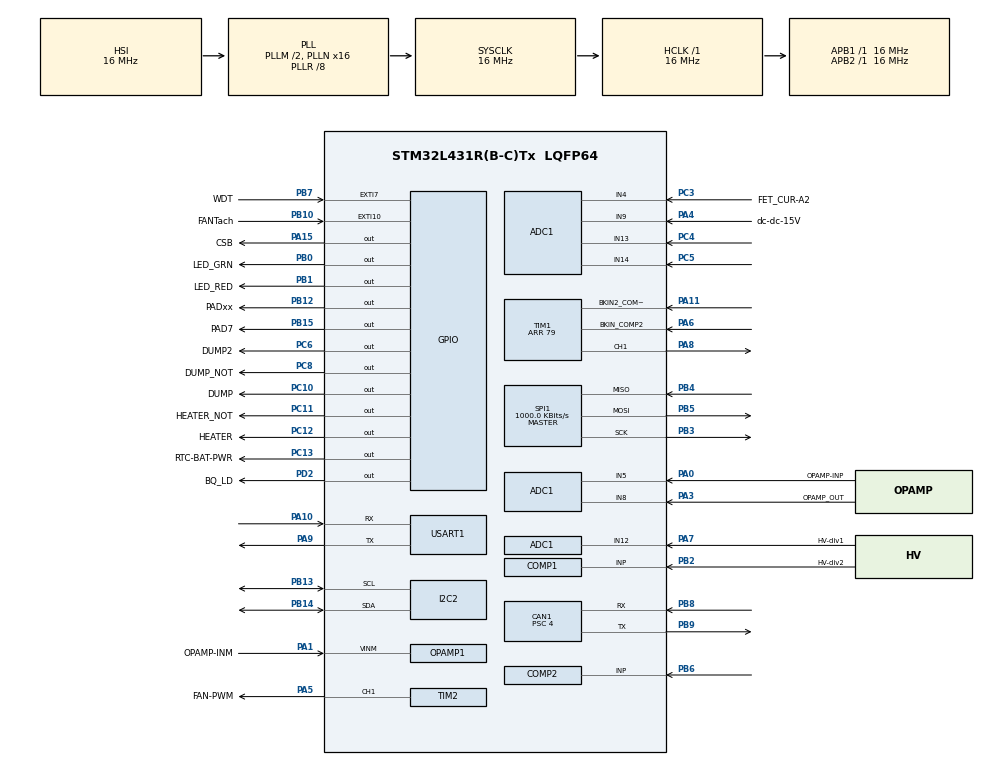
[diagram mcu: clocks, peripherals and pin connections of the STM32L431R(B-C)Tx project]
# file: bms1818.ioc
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ADC1.Channel-0\#ChannelRegularConversion=ADC_CHANNEL_4
ADC1.Channel-1\#ChannelRegularConversion=ADC_CHANNEL_5
ADC1.Channel-2\#ChannelRegularConversion=ADC_CHANNEL_8
ADC1.Channel-3\#ChannelRegularConversion=ADC_CHANNEL_12
ADC1.Channel-4\#ChannelRegularConversion=ADC_CHANNEL_13
ADC1.Channel-5\#ChannelRegularConversion=ADC_CHANNEL_14
ADC1.Channel-6\#ChannelRegularConversion=ADC_CHANNEL_VREFINT
ADC1.Channel-7\#ChannelRegularConversion=ADC_CHANNEL_TEMPSENSOR
ADC1.Channel-8\#ChannelRegularConversion=ADC_CHANNEL_9
ADC1.ContinuousConvMode=ENABLE
ADC1.DMAContinuousRequests=ENABLE
ADC1.EOCSelection=ADC_EOC_SEQ_CONV
ADC1.EnableInjectedConversion=DISABLE
ADC1.NbrOfConversion=9
ADC1.NbrOfConversionFlag=1
ADC1.OffsetNumber-0\#ChannelRegularConversion=ADC_OFFSET_NONE
ADC1.OffsetNumber-1\#ChannelRegularConversion=ADC_OFFSET_NONE
ADC1.OffsetNumber-2\#ChannelRegularConversion=ADC_OFFSET_NONE
ADC1.OffsetNumber-3\#ChannelRegularConversion=ADC_OFFSET_NONE
ADC1.OffsetNumber-4\#ChannelRegularConversion=ADC_OFFSET_NONE
ADC1.OffsetNumber-5\#ChannelRegularConversion=ADC_OFFSET_NONE
ADC1.OffsetNumber-6\#ChannelRegularConversion=ADC_OFFSET_NONE
ADC1.OffsetNumber-7\#ChannelRegularConversion=ADC_OFFSET_NONE
ADC1.OffsetNumber-8\#ChannelRegularConversion=ADC_OFFSET_NONE
ADC1.OversamplingMode=ENABLE
ADC1.Rank-0\#ChannelRegularConversion=1
ADC1.Rank-1\#ChannelRegularConversion=2
ADC1.Rank-2\#ChannelRegularConversion=3
ADC1.Rank-3\#ChannelRegularConversion=4
ADC1.Rank-4\#ChannelRegularConversion=5
ADC1.Rank-5\#ChannelRegularConversion=6
ADC1.Rank-6\#ChannelRegularConversion=7
ADC1.Rank-7\#ChannelRegularConversion=8
ADC1.Rank-8\#ChannelRegularConversion=9
ADC1.Ratio=ADC_OVERSAMPLING_RATIO_16
ADC1.SamplingTime-0\#ChannelRegularConversion=ADC_SAMPLETIME_2CYCLES_5
ADC1.SamplingTime-1\#ChannelRegularConversion=ADC_SAMPLETIME_24CYCLES_5
ADC1.SamplingTime-2\#ChannelRegularConversion=ADC_SAMPLETIME_24CYCLES_5
ADC1.SamplingTime-3\#ChannelRegularConversion=ADC_SAMPLETIME_640CYCLES_5
ADC1.SamplingTime-4\#ChannelRegularConversion=ADC_SAMPLETIME_247CYCLES_5
ADC1.SamplingTime-5\#ChannelRegularConversion=ADC_SAMPLETIME_247CYCLES_5
ADC1.SamplingTime-6\#ChannelRegularConversion=ADC_SAMPLETIME_247CYCLES_5
ADC1.SamplingTime-7\#ChannelRegularConversion=ADC_SAMPLETIME_247CYCLES_5
ADC1.SamplingTime-8\#ChannelRegularConversion=ADC_SAMPLETIME_247CYCLES_5
ADC1.master=1
CAN1.BS1=CAN_BS1_5TQ
CAN1.BS2=CAN_BS2_2TQ
CAN1.CalculateBaudRate=500000
CAN1.CalculateTimeBit=2000.00
CAN1.CalculateTimeQuantum=250.0
CAN1.NART=ENABLE
CAN1.Prescaler=4
CAN1.SJW=CAN_SJW_1TQ
COMP1.BlankingSrce=COMP_BLANKINGSRC_NONE
COMP2.BlankingSrce=COMP_BLANKINGSRC_NONE
DAC1.DAC_Channel-DAC_OUT2_Int=DAC_CHANNEL_2
Dma.ADC1.2.Direction=DMA_PERIPH_TO_MEMORY
Dma.ADC1.2.Instance=DMA1_Channel1
Dma.ADC1.2.MemDataAlignment=DMA_MDATAALIGN_HALFWORD
Dma.ADC1.2.MemInc=DMA_MINC_ENABLE
Dma.ADC1.2.Mode=DMA_CIRCULAR
Dma.ADC1.2.PeriphDataAlignment=DMA_PDATAALIGN_HALFWORD
Dma.ADC1.2.PeriphInc=DMA_PINC_DISABLE
Dma.ADC1.2.Priority=DMA_PRIORITY_LOW
Dma.I2C2_RX.3.Direction=DMA_PERIPH_TO_MEMORY
Dma.I2C2_RX.3.Instance=DMA1_Channel5
Dma.I2C2_RX.3.MemDataAlignment=DMA_MDATAALIGN_BYTE
Dma.I2C2_RX.3.MemInc=DMA_MINC_ENABLE
Dma.I2C2_RX.3.Mode=DMA_NORMAL
Dma.I2C2_RX.3.PeriphDataAlignment=DMA_PDATAALIGN_BYTE
Dma.I2C2_RX.3.PeriphInc=DMA_PINC_DISABLE
Dma.I2C2_RX.3.Priority=DMA_PRIORITY_LOW
Dma.I2C2_TX.4.Direction=DMA_MEMORY_TO_PERIPH
Dma.I2C2_TX.4.Instance=DMA1_Channel4
Dma.I2C2_TX.4.MemDataAlignment=DMA_MDATAALIGN_BYTE
Dma.I2C2_TX.4.MemInc=DMA_MINC_ENABLE
Dma.I2C2_TX.4.Mode=DMA_NORMAL
Dma.I2C2_TX.4.PeriphDataAlignment=DMA_PDATAALIGN_BYTE
Dma.I2C2_TX.4.PeriphInc=DMA_PINC_DISABLE
Dma.I2C2_TX.4.Priority=DMA_PRIORITY_LOW
Dma.Request0=USART1_RX
Dma.Request1=USART1_TX
Dma.Request2=ADC1
Dma.Request3=I2C2_RX
Dma.Request4=I2C2_TX
Dma.Request5=SPI1_RX
Dma.Request6=SPI1_TX
Dma.SPI1_RX.5.Direction=DMA_PERIPH_TO_MEMORY
Dma.SPI1_RX.5.Instance=DMA1_Channel2
Dma.SPI1_RX.5.MemDataAlignment=DMA_MDATAALIGN_BYTE
Dma.SPI1_RX.5.MemInc=DMA_MINC_ENABLE
Dma.SPI1_RX.5.Mode=DMA_NORMAL
Dma.SPI1_RX.5.PeriphDataAlignment=DMA_PDATAALIGN_BYTE
Dma.SPI1_RX.5.PeriphInc=DMA_PINC_DISABLE
Dma.SPI1_RX.5.Priority=DMA_PRIORITY_LOW
Dma.SPI1_TX.6.Direction=DMA_MEMORY_TO_PERIPH
Dma.SPI1_TX.6.Instance=DMA1_Channel3
Dma.SPI1_TX.6.MemDataAlignment=DMA_MDATAALIGN_BYTE
Dma.SPI1_TX.6.MemInc=DMA_MINC_ENABLE
Dma.SPI1_TX.6.Mode=DMA_NORMAL
Dma.SPI1_TX.6.PeriphDataAlignment=DMA_PDATAALIGN_BYTE
Dma.SPI1_TX.6.PeriphInc=DMA_PINC_DISABLE
Dma.SPI1_TX.6.Priority=DMA_PRIORITY_LOW
Dma.USART1_RX.0.Direction=DMA_PERIPH_TO_MEMORY
Dma.USART1_RX.0.Instance=DMA2_Channel7
Dma.USART1_RX.0.MemDataAlignment=DMA_MDATAALIGN_BYTE
Dma.USART1_RX.0.MemInc=DMA_MINC_ENABLE
Dma.USART1_RX.0.Mode=DMA_CIRCULAR
Dma.USART1_RX.0.PeriphDataAlignment=DMA_PDATAALIGN_BYTE
Dma.USART1_RX.0.PeriphInc=DMA_PINC_DISABLE
Dma.USART1_RX.0.Priority=DMA_PRIORITY_LOW
Dma.USART1_TX.1.Direction=DMA_MEMORY_TO_PERIPH
Dma.USART1_TX.1.Instance=DMA2_Channel6
Dma.USART1_TX.1.MemDataAlignment=DMA_MDATAALIGN_BYTE
Dma.USART1_TX.1.MemInc=DMA_MINC_ENABLE
Dma.USART1_TX.1.Mode=DMA_NORMAL
Dma.USART1_TX.1.PeriphDataAlignment=DMA_PDATAALIGN_BYTE
Dma.USART1_TX.1.PeriphInc=DMA_PINC_DISABLE
Dma.USART1_TX.1.Priority=DMA_PRIORITY_LOW
FREERTOS.Tasks01=defaultTask,24,448,StartDefaultTask,Default,NULL,Dynamic,NULL,NULL
FREERTOS.configTOTAL_HEAP_SIZE=12000
I2C2.Timing=0x00303D5B
Mcu.Family=STM32L4
Mcu.Name=STM32L431R(B-C)Tx
Mcu.Package=LQFP64
NVIC.CAN1_RX0_IRQn=true\:7\:0\:true\:false\:true\:true\:true\:true
NVIC.CAN1_RX1_IRQn=true\:7\:0\:true\:false\:true\:true\:true\:true
NVIC.CAN1_TX_IRQn=true\:7\:0\:true\:false\:true\:true\:true\:true
NVIC.DMA1_Channel1_IRQn=true\:6\:0\:true\:false\:true\:true\:false\:true
NVIC.DMA1_Channel2_IRQn=true\:5\:0\:false\:false\:true\:true\:false\:true
NVIC.DMA1_Channel3_IRQn=true\:5\:0\:false\:false\:true\:true\:false\:true
NVIC.DMA1_Channel4_IRQn=true\:5\:0\:false\:false\:true\:true\:false\:true
NVIC.DMA1_Channel5_IRQn=true\:5\:0\:false\:false\:true\:true\:false\:true
NVIC.DMA2_Channel6_IRQn=true\:6\:0\:true\:false\:true\:false\:false\:true
NVIC.DMA2_Channel7_IRQn=true\:6\:0\:true\:false\:true\:false\:false\:true
NVIC.EXTI9_5_IRQn=true\:5\:0\:false\:false\:true\:true\:true\:true
NVIC.PriorityGroup=NVIC_PRIORITYGROUP_4
NVIC.TIM1_BRK_TIM15_IRQn=true\:5\:0\:false\:false\:true\:true\:true\:true
NVIC.TIM1_UP_TIM16_IRQn=true\:0\:0\:false\:false\:true\:false\:false\:true
NVIC.TimeBase=TIM1_UP_TIM16_IRQn
NVIC.TimeBaseIP=TIM16
NVIC.USART1_IRQn=true\:10\:0\:true\:false\:true\:true\:true\:true
OPAMP1.PgaGain=OPAMP_PGA_GAIN_8
OPAMP1.PowerSupplyRange=OPAMP_POWERSUPPLY_HIGH
PA0.GPIO_Label=OPAMP-INP
PA0.Signal=SharedAnalog_PA0
PA1.GPIO_Label=OPAMP-INM
PA1.Signal=SharedAnalog_PA1
PA10.Mode=Asynchronous
PA10.Signal=USART1_RX
PA11.Mode=ExternalOutput_TIM1BKIN2
PA11.Signal=TIM1_BKIN2_COMP1
PA13\ (JTMS-SWDIO).Mode=Serial_Wire
PA13\ (JTMS-SWDIO).Signal=SYS_JTMS-SWDIO
PA14\ (JTCK-SWCLK).Mode=Serial_Wire
PA14\ (JTCK-SWCLK).Signal=SYS_JTCK-SWCLK
PA15\ (JTDI).GPIO_Label=CSB
PA15\ (JTDI).GPIO_Speed=GPIO_SPEED_FREQ_HIGH
PA15\ (JTDI).Signal=GPIO_Output
PA3.GPIO_Label=OPAMP_OUT
PA3.Signal=SharedAnalog_PA3
PA4.GPIO_Label=dc-dc-15V
PA4.Signal=SharedAnalog_PA4
PA5.GPIO_Label=FAN-PWM
PA5.Signal=S_TIM2_CH1
PA6.Mode=ExternalOutput_TIM1BKIN
PA6.Signal=TIM1_BKIN_COMP2
PA7.GPIO_Label=HV-div1
PA7.Signal=SharedAnalog_PA7
PA8.Signal=S_TIM1_CH1
PA9.Mode=Asynchronous
PA9.Signal=USART1_TX
PB0.GPIO_Label=LED_GRN
PB0.PinState=GPIO_PIN_SET
PB0.Signal=GPIO_Output
PB1.GPIO_Label=LED_RED
PB1.PinState=GPIO_PIN_SET
PB1.Signal=GPIO_Output
PB10.GPIO_Label=FANTach
PB10.Signal=GPXTI10
PB12.GPIO_Label=PADxx
PB12.Signal=GPIO_Output
PB13.GPIO_Pu=GPIO_NOPULL
PB13.GPIO_Speed=GPIO_SPEED_FREQ_LOW
PB13.Mode=I2C
PB13.Signal=I2C2_SCL
PB14.GPIO_Pu=GPIO_NOPULL
PB14.Mode=I2C
PB14.Signal=I2C2_SDA
PB15.GPIO_Label=PAD7
PB15.Signal=GPIO_Output
PB2.GPIO_Label=HV-div2
PB2.Signal=SharedAnalog_PB2
PB3\ (JTDO-TRACESWO).Mode=Full_Duplex_Master
PB3\ (JTDO-TRACESWO).Signal=SPI1_SCK
PB4\ (NJTRST).Mode=Full_Duplex_Master
PB4\ (NJTRST).Signal=SPI1_MISO
PB5.Mode=Full_Duplex_Master
PB5.Signal=SPI1_MOSI
PB6.Mode=INP
PB6.Signal=COMP2_INP
PB7.GPIO_Label=WDT
PB7.GPIO_PuPd=GPIO_PULLUP
PB7.Signal=GPXTI7
PB8.Mode=CAN_Activate
PB8.Signal=CAN1_RX
PB9.Mode=CAN_Activate
PB9.Signal=CAN1_TX
PC10.GPIO_Label=DUMP
PC10.Signal=GPIO_Output
PC11.GPIO_Label=HEATER_NOT
PC11.Signal=GPIO_Output
PC12.GPIO_Label=HEATER
PC12.Signal=GPIO_Output
PC13.GPIO_Label=RTC-BAT-PWR
PC13.Signal=GPIO_Output
PC3.GPIO_Label=FET_CUR-A2
PC3.Signal=SharedAnalog_PC3
PC4.Signal=ADCx_IN13
PC5.Signal=ADCx_IN14
PC6.GPIO_Label=DUMP2
PC6.GPIO_PuPd=GPIO_PULLDOWN
PC6.Signal=GPIO_Output
PC8.GPIO_Label=DUMP_NOT
PC8.Signal=GPIO_Output
PD2.GPIO_Label=BQ_LD
PD2.Signal=GPIO_Output
PH0-OSC_IN\ (PH0).Mode=HSE-External-Oscillator
PH0-OSC_IN\ (PH0).Signal=RCC_OSC_IN
PH1-OSC_OUT\ (PH1).Mode=HSE-External-Oscillator
PH1-OSC_OUT\ (PH1).Signal=RCC_OSC_OUT
ProjectManager.HeapSize=0x200
ProjectManager.StackSize=0x400
ProjectManager.TargetToolchain=Makefile
RCC.ADCFreq_Value=16000000
RCC.AHBFreq_Value=16000000
RCC.APB1Freq_Value=16000000
RCC.APB1TimFreq_Value=16000000
RCC.APB2Freq_Value=16000000
RCC.APB2TimFreq_Value=16000000
RCC.CortexFreq_Value=16000000
RCC.HCLKFreq_Value=16000000
RCC.HSE_VALUE=16000000
RCC.HSI48_VALUE=48000000
RCC.HSI_VALUE=16000000
RCC.I2C1CLockSelection=RCC_I2C1CLKSOURCE_SYSCLK
RCC.MSIClockRange=RCC_MSIRANGE_7
RCC.MSI_VALUE=8000000
RCC.PLLM=2
RCC.PLLN=16
RCC.PLLR=RCC_PLLR_DIV8
RCC.PLLSAI1R=RCC_PLLR_DIV4
RCC.PLLSourceVirtual=RCC_PLLSOURCE_HSI
RCC.SYSCLKFreq_VALUE=16000000
RCC.SYSCLKSource=RCC_SYSCLKSOURCE_PLLCLK
RCC.USART1CLockSelection=RCC_USART1CLKSOURCE_HSI
RCC.VCOOutputFreq_Value=128000000
SH.ADCx_IN13.0=ADC1_IN13,IN13-Single-Ended
SH.ADCx_IN14.0=ADC1_IN14,IN14-Single-Ended
SH.S_TIM1_CH1.0=TIM1_CH1,PWM Generation1 CH1
SH.S_TIM2_CH1.0=TIM2_CH1,PWM Generation1 CH1
SH.SharedAnalog_PA0.0=GPIO_Analog
SH.SharedAnalog_PA0.1=ADC1_IN5,IN5-Single-Ended
SH.SharedAnalog_PA0.2=OPAMP1_VINP,PGA Connected
SH.SharedAnalog_PA1.0=GPIO_Analog
SH.SharedAnalog_PA1.1=OPAMP1_VINM,PGA Connected
SH.SharedAnalog_PA3.0=GPIO_Analog
SH.SharedAnalog_PA3.1=ADC1_IN8,IN8-Single-Ended
SH.SharedAnalog_PA3.2=OPAMP1_VOUT,PGA Connected
SH.SharedAnalog_PA4.0=GPIO_Analog
SH.SharedAnalog_PA4.1=ADC1_IN9,IN9-Single-Ended
SH.SharedAnalog_PA7.0=GPIO_Analog
SH.SharedAnalog_PA7.1=ADC1_IN12,IN12-Single-Ended
SH.SharedAnalog_PB2.0=GPIO_Analog
SH.SharedAnalog_PB2.1=COMP1_INP,INP
SH.SharedAnalog_PC3.0=GPIO_Analog
SH.SharedAnalog_PC3.1=ADC1_IN4,IN4-Single-Ended
SPI1.BaudRatePrescaler=SPI_BAUDRATEPRESCALER_16
SPI1.CLKPolarity=SPI_POLARITY_HIGH
SPI1.CalculateBaudRate=1000.0 KBits/s
SPI1.DataSize=SPI_DATASIZE_8BIT
SPI1.Direction=SPI_DIRECTION_2LINES
SPI1.Mode=SPI_MODE_MASTER
SPI1.NSSPMode=SPI_NSS_PULSE_DISABLE
SPI1.VirtualType=VM_MASTER
TIM1.AutomaticOutput=TIM_AUTOMATICOUTPUT_ENABLE
TIM1.Channel-PWM\ Generation1\ CH1=TIM_CHANNEL_1
TIM1.Period=79
TIM1.SourceBRK2COMP1=TIM_BREAKINPUTSOURCE_ENABLE
TIM1.SourceBRK2COMP2=TIM_BREAKINPUTSOURCE_DISABLE
TIM1.SourceBRKCOMP2=TIM_BREAKINPUTSOURCE_ENABLE
TIM15.Channel-Output\ Compare1\ No\ Output=TIM_CHANNEL_1
TIM15.Prescaler=16
TIM2.Channel-PWM\ Generation1\ CH1=TIM_CHANNEL_1
USART1.OverSampling=UART_OVERSAMPLING_8
USART1.VirtualMode-Asynchronous=VM_ASYNC
VP_ADC1_TempSens_Input.Mode=IN-TempSens
VP_ADC1_Vref_Input.Mode=IN-Vrefint
VP_COMP1_VS_DACOUT1.Mode=INM_DACOUT1
VP_COMP2_VS_DACOUT2.Mode=INM_DACOUT2
VP_DAC1_VS_DACI1.Mode=DAC_OUT1_Int
VP_DAC1_VS_DACI2.Mode=DAC_OUT2_Int
VP_FREERTOS_VS_CMSIS_V2.Mode=CMSIS_V2
VP_RTC_VS_RTC_Activate.Mode=RTC_Enabled
VP_RTC_VS_RTC_Calendar.Mode=RTC_Calendar
VP_SYS_VS_tim16.Mode=TIM16
VP_TIM15_VS_ClockSourceINT.Mode=Internal
VP_TIM15_VS_no_output1.Mode=Output Compare1 No Output
VP_TIM1_VS_BKIN2_COMP1.Mode=Activate-Break-Input-2-COMP1
VP_TIM1_VS_BKIN_COMP2.Mode=Activate-Break-Input-COMP2
VP_TIM1_VS_ClockSourceINT.Mode=Internal
VP_TIM2_VS_ClockSourceINT.Mode=Internal
board=custom

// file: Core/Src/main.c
/* USER CODE BEGIN Header */
/**
  ******************************************************************************
  * @file           : main.c
  * @brief          : Main program body
  ******************************************************************************
  * @attention
  *
  * <h2><center>&copy; Copyright (c) 2021 STMicroelectronics.
  * All rights reserved.</center></h2>
  *
  * This software component is licensed by ST under Ultimate Liberty license
  * SLA0044, the "License"; You may not use this file except in compliance with
  * the License. You may obtain a copy of the License at:
  *                             www.st.com/SLA0044
  *
  ******************************************************************************
  */
/*Command line to load program over CAN
:~~/GliderWinchCommons/embed/svn_discoveryf4/PC/sensor/CANldr/trunk$ ./CANldr 127.0.0.1 32123 B0A00000 ~/GliderWinchItems/BMS/bmsadbms1818/build/bms1818.xbin; echo $?
*/
/* USER CODE END Header */
#include "main.h"
#include "cmsis_os.h"

/* USER CODE BEGIN Includes */
#include <string.h>
#include "morse.h"
#include "DTW_counter.h"
#include "fetonoff.h"

#include "adcparams.h"
#include "SerialTaskSend.h"
#include "SerialTaskReceive.h"
#include "CanTask.h"
#include "can_iface.h"
#include "canfilter_setup.h"
#include "getserialbuf.h"
#include "yprintf.h"
#include "DTW_counter.h"
#include "BQTask.h"
#include "bqview.h"
#include "bqcellbal.h"
#include "bq_func_init.h"
#include "bq_items.h"
#include "ADCTask.h"
#include "MailboxTask.h"
#include "CanCommTask.h"
#include "BMSTask.h"
#include "fanop.h"
#include "chgr_items.h"
#include "bmsspi.h"
#include "bms_items.h"
#include "rtcregs.h"

#include "FreeRTOS.h"
#include "semphr.h"
/* USER CODE END Includes */

/* USER CODE BEGIN PTD */
uint32_t timectr = 0;
struct CAN_CTLBLOCK* pctl0; // Pointer to CAN1 control block
//struct CAN_CTLBLOCK* pctl1; // Pointer to CAN2 control block

uint32_t debugTX1b;
uint32_t debugTX1b_prev;

uint32_t debugTX1c;
uint32_t debugTX1c_prev;

uint32_t debug03;
uint32_t debug03_prev;

uint32_t dbgwarning;

//extern osThreadId SerialTaskHandle;
//extern osThreadId CanTxTaskHandle;
//extern osThreadId CanRxTaskHandle;
//extern osThreadId SerialTaskReceiveHandle;

uint16_t m_trap = 450; // Trap codes for MX Init() and Error Handler

uint8_t canflag;
uint8_t canflag1;
//uint8_t canflag2;

int8_t rtcregs_ret; // RTC register init return

const uint32_t i_am_canid = I_AM_CANID;

/* USER CODE END PTD */

/* USER CODE BEGIN PM */
  /*
  Timer usage
                         1    2   3   4   auto  auto
  TIM1 charger control  PWM   x   x   x  comp1 comp2
                        PA8               PA6   PA11
  TIM2 FAN PWM TACH     PWM   x  IC   x
                        PA5     PB10
  TIM7  System          x

  TIM15 SPI/ADC/BMS     OC    x

  */
/* USER CODE END PM */

ADC_HandleTypeDef hadc1;
DMA_HandleTypeDef hdma_adc1;

CAN_HandleTypeDef hcan1;

COMP_HandleTypeDef hcomp1;
COMP_HandleTypeDef hcomp2;

DAC_HandleTypeDef hdac1;

I2C_HandleTypeDef hi2c2;
DMA_HandleTypeDef hdma_i2c2_rx;
DMA_HandleTypeDef hdma_i2c2_tx;

OPAMP_HandleTypeDef hopamp1;

RTC_HandleTypeDef hrtc;

SPI_HandleTypeDef hspi1;
DMA_HandleTypeDef hdma_spi1_rx;
DMA_HandleTypeDef hdma_spi1_tx;

TIM_HandleTypeDef htim1;
TIM_HandleTypeDef htim2;
TIM_HandleTypeDef htim15;

UART_HandleTypeDef huart1;
DMA_HandleTypeDef hdma_usart1_rx;
DMA_HandleTypeDef hdma_usart1_tx;

/* Definitions for defaultTask */
osThreadId_t defaultTaskHandle;
const osThreadAttr_t defaultTask_attributes = {
  .name = "defaultTask",
  .stack_size = 448 * 4,
  .priority = (osPriority_t) osPriorityNormal,
};
/* USER CODE BEGIN PV */
uint16_t errorcode;
/* USER CODE END PV */

void SystemClock_Config(void);
static void MX_GPIO_Init(void);
static void MX_DMA_Init(void);
static void MX_ADC1_Init(void);
static void MX_CAN1_Init(void);
static void MX_RTC_Init(void);
static void MX_TIM2_Init(void);
static void MX_USART1_UART_Init(void);
static void MX_COMP1_Init(void);
static void MX_DAC1_Init(void);
static void MX_TIM1_Init(void);
static void MX_TIM15_Init(void);
static void MX_OPAMP1_Init(void);
static void MX_SPI1_Init(void);
static void MX_I2C2_Init(void);
static void MX_COMP2_Init(void);
void StartDefaultTask(void *argument);

int main(void)
{
  /* USER CODE BEGIN 1 */
  BaseType_t ret;    // Used for returns from function calls
  osThreadId Thrdret;  // Return from thread create
  /* USER CODE END 1 */

  /* MCU Configuration--------------------------------------------------------*/

  /* Reset of all peripherals, Initializes the Flash interface and the Systick. */
  HAL_Init();

  /* USER CODE BEGIN Init */
  DTW_counter_init();
  /* USER CODE END Init */

  /* Configure the system clock */
  SystemClock_Config();

  /* USER CODE BEGIN SysInit */
#define NUMCIRBCB1  16 // Size of circular buffer of BCB for usart3
  ret = xSerialTaskSendAdd(&HUARTMON, NUMCIRBCB1, 1); // dma
  if (ret < 0) morse_trap(111); // Panic LED flashing
  /* USER CODE END SysInit */

  /* Initialize all configured peripherals */
  MX_GPIO_Init();
  MX_DMA_Init();
  MX_ADC1_Init();
  MX_CAN1_Init();
  MX_RTC_Init();
  MX_TIM2_Init();
  MX_USART1_UART_Init();
  MX_COMP1_Init();
  MX_DAC1_Init();
  MX_TIM1_Init();
  MX_TIM15_Init();
  MX_OPAMP1_Init();
  MX_SPI1_Init();
  MX_I2C2_Init();
  MX_COMP2_Init();
  /* USER CODE BEGIN 2 */
  /* CAN ID for this node is passed in to make from command line. */
//  i_am_canid = I_AM_CANID;
  /* USER CODE END 2 */

  /* Init scheduler */
  osKernelInitialize();

  /* USER CODE BEGIN RTOS_SEMAPHORES */
  /* add semaphores, ... */
  /* Setup semaphore for yprint and sprintf et al. */
  yprintf_init();
  /* USER CODE END RTOS_SEMAPHORES */

  /* Create the thread(s) */
  /* creation of defaultTask */
  defaultTaskHandle = osThreadNew(StartDefaultTask, NULL, &defaultTask_attributes);

  /* USER CODE BEGIN RTOS_THREADS */
  /* add threads, ... */

  Thrdret = xADCTaskCreate(osPriorityNormal+2); // (arg) = priority
  if (Thrdret == NULL) morse_trap(117);

  /* Create serial task (priority) */
  // Task handle "osThreadId SerialTaskHandle" is global
  Thrdret = xSerialTaskSendCreate(osPriorityNormal); // Create task and set Task priority
  if (Thrdret == NULL) morse_trap(112);

    /* Add bcb circular buffer to SerialTaskSend for usart3 -- PC monitor */
  #define NUMCIRBCB3  16 // Size of circular buffer of BCB for usart3
  ret = xSerialTaskSendAdd(&HUARTMON, NUMCIRBCB3, 1); // dma
  if (ret < 0) morse_trap(14); // Panic LED flashing

  /* Setup TX linked list for CAN  */
   // CAN1 (CAN_HandleTypeDef *phcan, uint8_t canidx, uint16_t numtx, uint16_t numrx);
  pctl0 = can_iface_init(&hcan1, 0, 96, 32);
  if (pctl0 == NULL) morse_trap(118); // Panic LED flashing
  if (pctl0->ret < 0) morse_trap(119);

  /* Create serial receiving task. */
  //ret = xSerialTaskReceiveCreate(osPriorityNormal);
  //if (ret != pdPASS) morse_trap(113);

  /* BQTask. */
//  TaskHandle_t retT = xBQTaskCreate(osPriorityNormal);
//  if (retT == NULL) morse_trap(114);

  /* USER CODE END RTOS_THREADS */

  /* USER CODE BEGIN RTOS_EVENTS */
  /* add events, ... */
  // Initialize struct for BQ. */
  bq_func_init();

  /* definition and creation of CanTxTask - CAN driver TX interface. */
  QueueHandle_t QHret = xCanTxTaskCreate(osPriorityNormal+1, 48); // CanTask priority, Number of msgs in queue
  if (QHret == NULL) morse_trap(120); // Panic LED flashing

  /* definition and creation of CanRxTask - CAN driver RX interface. */
  /* The MailboxTask takes care of the CANRx                         */
//  Qidret = xCanRxTaskCreate(1, 32); // CanTask priority, Number of msgs in queue
//  if (Qidret < 0) morse_trap(6); // Panic LED flashing

  /* Create MailboxTask */
  xMailboxTaskCreate(osPriorityNormal+1); // (arg) = priority

  /* Create Mailbox control block w 'take' pointer for each CAN module. */
  struct MAILBOXCANNUM* pmbxret;
  // (CAN1 control block pointer, size of circular buffer)
  pmbxret = MailboxTask_add_CANlist(pctl0, 32);
  if (pmbxret == NULL) morse_trap(215);

  /* Setup CAN hardware filters to default to accept all ids. */
  HAL_StatusTypeDef Cret;
  Cret = canfilter_setup_first(0, &hcan1, 15); // CAN1
  if (Cret == HAL_ERROR) morse_trap(122);

  TaskHandle_t retT = xBMSTaskCreate(osPriorityNormal+2);
//  TaskHandle_t retT = xBMSTaskCreate(osPriorityNormal+1);
  if (retT == NULL) morse_trap(123);

  /* CAN communication */
  retT = xCanCommCreate(osPriorityNormal+2);
  if (retT == NULL) morse_trap(121);

    /* Select interrupts for CAN1 */
  HAL_CAN_ActivateNotification(&hcan1, \
    CAN_IT_TX_MAILBOX_EMPTY     |  \
    CAN_IT_RX_FIFO0_MSG_PENDING |  \
    CAN_IT_RX_FIFO1_MSG_PENDING    );

  /* Init some things used by tasks. */
  //bq_func_init();
  chgr_items_init();
  fanop_init();
  bmsspi_preinit();
  rtcregs_ret = rtcregs_init();

  /* This will run the 5 and 3.3v regulators from the ribbon
     Cell #3 when the CAN power has been removed. */
  HAL_GPIO_WritePin(GPIOC,GPIO_PIN_13,GPIO_PIN_SET); // ON
//HAL_GPIO_WritePin(GPIOC,GPIO_PIN_13,GPIO_PIN_RESET); // OFF
  /* USER CODE END RTOS_EVENTS */

  /* Start scheduler */
  osKernelStart();

  /* We should never get here as control is now taken by the scheduler */
  /* Infinite loop */
  while (1)
  {

  }
}

void SystemClock_Config(void)
{
  RCC_OscInitTypeDef RCC_OscInitStruct = {0};
  RCC_ClkInitTypeDef RCC_ClkInitStruct = {0};

  /** Configure the main internal regulator output voltage
  */
  if (HAL_PWREx_ControlVoltageScaling(PWR_REGULATOR_VOLTAGE_SCALE1) != HAL_OK)
  {
    Error_Handler();
  }
  /** Initializes the RCC Oscillators according to the specified parameters
  * in the RCC_OscInitTypeDef structure.
  */
  RCC_OscInitStruct.OscillatorType = RCC_OSCILLATORTYPE_HSI|RCC_OSCILLATORTYPE_LSI;
  RCC_OscInitStruct.HSIState = RCC_HSI_ON;
  RCC_OscInitStruct.HSICalibrationValue = RCC_HSICALIBRATION_DEFAULT;
  RCC_OscInitStruct.LSIState = RCC_LSI_ON;
  RCC_OscInitStruct.PLL.PLLState = RCC_PLL_ON;
  RCC_OscInitStruct.PLL.PLLSource = RCC_PLLSOURCE_HSI;
  RCC_OscInitStruct.PLL.PLLM = 2;
  RCC_OscInitStruct.PLL.PLLN = 16;
  RCC_OscInitStruct.PLL.PLLP = RCC_PLLP_DIV7;
  RCC_OscInitStruct.PLL.PLLQ = RCC_PLLQ_DIV2;
  RCC_OscInitStruct.PLL.PLLR = RCC_PLLR_DIV8;
  if (HAL_RCC_OscConfig(&RCC_OscInitStruct) != HAL_OK)
  {
    Error_Handler();
  }
  /** Initializes the CPU, AHB and APB buses clocks
  */
  RCC_ClkInitStruct.ClockType = RCC_CLOCKTYPE_HCLK|RCC_CLOCKTYPE_SYSCLK
                              |RCC_CLOCKTYPE_PCLK1|RCC_CLOCKTYPE_PCLK2;
  RCC_ClkInitStruct.SYSCLKSource = RCC_SYSCLKSOURCE_PLLCLK;
  RCC_ClkInitStruct.AHBCLKDivider = RCC_SYSCLK_DIV1;
  RCC_ClkInitStruct.APB1CLKDivider = RCC_HCLK_DIV1;
  RCC_ClkInitStruct.APB2CLKDivider = RCC_HCLK_DIV1;

  if (HAL_RCC_ClockConfig(&RCC_ClkInitStruct, FLASH_LATENCY_0) != HAL_OK)
  {
    Error_Handler();
  }
}

static void MX_ADC1_Init(void)
{

  ADC_ChannelConfTypeDef sConfig = {0};

  /** Common config
  */
  hadc1.Instance = ADC1;
  hadc1.Init.ClockPrescaler = ADC_CLOCK_ASYNC_DIV1;
  hadc1.Init.Resolution = ADC_RESOLUTION_12B;
  hadc1.Init.DataAlign = ADC_DATAALIGN_RIGHT;
  hadc1.Init.ScanConvMode = ADC_SCAN_ENABLE;
  hadc1.Init.EOCSelection = ADC_EOC_SEQ_CONV;
  hadc1.Init.LowPowerAutoWait = DISABLE;
  hadc1.Init.ContinuousConvMode = ENABLE;
  hadc1.Init.NbrOfConversion = 9;
  hadc1.Init.DiscontinuousConvMode = DISABLE;
  hadc1.Init.ExternalTrigConv = ADC_SOFTWARE_START;
  hadc1.Init.ExternalTrigConvEdge = ADC_EXTERNALTRIGCONVEDGE_NONE;
  hadc1.Init.DMAContinuousRequests = ENABLE;
  hadc1.Init.Overrun = ADC_OVR_DATA_PRESERVED;
  hadc1.Init.OversamplingMode = ENABLE;
  hadc1.Init.Oversampling.Ratio = ADC_OVERSAMPLING_RATIO_16;
  hadc1.Init.Oversampling.RightBitShift = ADC_RIGHTBITSHIFT_NONE;
  hadc1.Init.Oversampling.TriggeredMode = ADC_TRIGGEREDMODE_SINGLE_TRIGGER;
  hadc1.Init.Oversampling.OversamplingStopReset = ADC_REGOVERSAMPLING_CONTINUED_MODE;
  if (HAL_ADC_Init(&hadc1) != HAL_OK)
  {
    Error_Handler();
  }
  /** Configure Regular Channel
  */
  sConfig.Channel = ADC_CHANNEL_4;
  sConfig.Rank = ADC_REGULAR_RANK_1;
  sConfig.SamplingTime = ADC_SAMPLETIME_2CYCLES_5;
  sConfig.SingleDiff = ADC_SINGLE_ENDED;
  sConfig.OffsetNumber = ADC_OFFSET_NONE;
  sConfig.Offset = 0;
  if (HAL_ADC_ConfigChannel(&hadc1, &sConfig) != HAL_OK)
  {
    Error_Handler();
  }
  /** Configure Regular Channel
  */
  sConfig.Channel = ADC_CHANNEL_5;
  sConfig.Rank = ADC_REGULAR_RANK_2;
  sConfig.SamplingTime = ADC_SAMPLETIME_24CYCLES_5;
  if (HAL_ADC_ConfigChannel(&hadc1, &sConfig) != HAL_OK)
  {
    Error_Handler();
  }
  /** Configure Regular Channel
  */
  sConfig.Channel = ADC_CHANNEL_8;
  sConfig.Rank = ADC_REGULAR_RANK_3;
  if (HAL_ADC_ConfigChannel(&hadc1, &sConfig) != HAL_OK)
  {
    Error_Handler();
  }
  /** Configure Regular Channel
  */
  sConfig.Channel = ADC_CHANNEL_12;
  sConfig.Rank = ADC_REGULAR_RANK_4;
  sConfig.SamplingTime = ADC_SAMPLETIME_640CYCLES_5;
  if (HAL_ADC_ConfigChannel(&hadc1, &sConfig) != HAL_OK)
  {
    Error_Handler();
  }
  /** Configure Regular Channel
  */
  sConfig.Channel = ADC_CHANNEL_13;
  sConfig.Rank = ADC_REGULAR_RANK_5;
  sConfig.SamplingTime = ADC_SAMPLETIME_247CYCLES_5;
  if (HAL_ADC_ConfigChannel(&hadc1, &sConfig) != HAL_OK)
  {
    Error_Handler();
  }
  /** Configure Regular Channel
  */
  sConfig.Channel = ADC_CHANNEL_14;
  sConfig.Rank = ADC_REGULAR_RANK_6;
  if (HAL_ADC_ConfigChannel(&hadc1, &sConfig) != HAL_OK)
  {
    Error_Handler();
  }
  /** Configure Regular Channel
  */
  sConfig.Channel = ADC_CHANNEL_VREFINT;
  sConfig.Rank = ADC_REGULAR_RANK_7;
  if (HAL_ADC_ConfigChannel(&hadc1, &sConfig) != HAL_OK)
  {
    Error_Handler();
  }
  /** Configure Regular Channel
  */
  sConfig.Channel = ADC_CHANNEL_TEMPSENSOR;
  sConfig.Rank = ADC_REGULAR_RANK_8;
  if (HAL_ADC_ConfigChannel(&hadc1, &sConfig) != HAL_OK)
  {
    Error_Handler();
  }
  /** Configure Regular Channel
  */
  sConfig.Channel = ADC_CHANNEL_9;
  sConfig.Rank = ADC_REGULAR_RANK_9;
  if (HAL_ADC_ConfigChannel(&hadc1, &sConfig) != HAL_OK)
  {
    Error_Handler();
  }

}

static void MX_CAN1_Init(void)
{

  hcan1.Instance = CAN1;
  hcan1.Init.Prescaler = 4;
  hcan1.Init.Mode = CAN_MODE_NORMAL;
  hcan1.Init.SyncJumpWidth = CAN_SJW_1TQ;
  hcan1.Init.TimeSeg1 = CAN_BS1_5TQ;
  hcan1.Init.TimeSeg2 = CAN_BS2_2TQ;
  hcan1.Init.TimeTriggeredMode = DISABLE;
  hcan1.Init.AutoBusOff = DISABLE;
  hcan1.Init.AutoWakeUp = DISABLE;
  hcan1.Init.AutoRetransmission = ENABLE;
  hcan1.Init.ReceiveFifoLocked = DISABLE;
  hcan1.Init.TransmitFifoPriority = DISABLE;
  if (HAL_CAN_Init(&hcan1) != HAL_OK)
  {
    Error_Handler();
  }

}

static void MX_COMP1_Init(void)
{

  /* USER CODE BEGIN COMP1_Init 0 */
  errorcode = 998; // Error_Handler morse_trap code

  /* USER CODE END COMP1_Init 0 */

  hcomp1.Instance = COMP1;
  hcomp1.Init.InvertingInput = COMP_INPUT_MINUS_DAC1_CH1;
  hcomp1.Init.NonInvertingInput = COMP_INPUT_PLUS_IO2;
  hcomp1.Init.OutputPol = COMP_OUTPUTPOL_NONINVERTED;
  hcomp1.Init.Hysteresis = COMP_HYSTERESIS_NONE;
  hcomp1.Init.BlankingSrce = COMP_BLANKINGSRC_NONE;
  hcomp1.Init.Mode = COMP_POWERMODE_HIGHSPEED;
  hcomp1.Init.WindowMode = COMP_WINDOWMODE_DISABLE;
  hcomp1.Init.TriggerMode = COMP_TRIGGERMODE_NONE;
  if (HAL_COMP_Init(&hcomp1) != HAL_OK)
  {
    Error_Handler();
  }

}

static void MX_COMP2_Init(void)
{

  /* USER CODE BEGIN COMP2_Init 0 */
  errorcode = 997; // Error_Handler morse_trap code

  /* USER CODE END COMP2_Init 0 */

  hcomp2.Instance = COMP2;
  hcomp2.Init.InvertingInput = COMP_INPUT_MINUS_DAC1_CH2;
  hcomp2.Init.NonInvertingInput = COMP_INPUT_PLUS_IO2;
  hcomp2.Init.OutputPol = COMP_OUTPUTPOL_NONINVERTED;
  hcomp2.Init.Hysteresis = COMP_HYSTERESIS_NONE;
  hcomp2.Init.BlankingSrce = COMP_BLANKINGSRC_NONE;
  hcomp2.Init.Mode = COMP_POWERMODE_HIGHSPEED;
  hcomp2.Init.WindowMode = COMP_WINDOWMODE_DISABLE;
  hcomp2.Init.TriggerMode = COMP_TRIGGERMODE_NONE;
  if (HAL_COMP_Init(&hcomp2) != HAL_OK)
  {
    Error_Handler();
  }

}

static void MX_DAC1_Init(void)
{

  DAC_ChannelConfTypeDef sConfig = {0};

  /** DAC Initialization
  */
  hdac1.Instance = DAC1;
  if (HAL_DAC_Init(&hdac1) != HAL_OK)
  {
    Error_Handler();
  }
  /** DAC channel OUT1 config
  */
  sConfig.DAC_SampleAndHold = DAC_SAMPLEANDHOLD_DISABLE;
  sConfig.DAC_Trigger = DAC_TRIGGER_NONE;
  sConfig.DAC_OutputBuffer = DAC_OUTPUTBUFFER_DISABLE;
  sConfig.DAC_ConnectOnChipPeripheral = DAC_CHIPCONNECT_ENABLE;
  sConfig.DAC_UserTrimming = DAC_TRIMMING_FACTORY;
  if (HAL_DAC_ConfigChannel(&hdac1, &sConfig, DAC_CHANNEL_1) != HAL_OK)
  {
    Error_Handler();
  }
  /** DAC channel OUT2 config
  */
  if (HAL_DAC_ConfigChannel(&hdac1, &sConfig, DAC_CHANNEL_2) != HAL_OK)
  {
    Error_Handler();
  }

}

static void MX_I2C2_Init(void)
{

  hi2c2.Instance = I2C2;
  hi2c2.Init.Timing = 0x00303D5B;
  hi2c2.Init.OwnAddress1 = 0;
  hi2c2.Init.AddressingMode = I2C_ADDRESSINGMODE_7BIT;
  hi2c2.Init.DualAddressMode = I2C_DUALADDRESS_DISABLE;
  hi2c2.Init.OwnAddress2 = 0;
  hi2c2.Init.OwnAddress2Masks = I2C_OA2_NOMASK;
  hi2c2.Init.GeneralCallMode = I2C_GENERALCALL_DISABLE;
  hi2c2.Init.NoStretchMode = I2C_NOSTRETCH_DISABLE;
  if (HAL_I2C_Init(&hi2c2) != HAL_OK)
  {
    Error_Handler();
  }
  /** Configure Analogue filter
  */
  if (HAL_I2CEx_ConfigAnalogFilter(&hi2c2, I2C_ANALOGFILTER_ENABLE) != HAL_OK)
  {
    Error_Handler();
  }
  /** Configure Digital filter
  */
  if (HAL_I2CEx_ConfigDigitalFilter(&hi2c2, 0) != HAL_OK)
  {
    Error_Handler();
  }

}

static void MX_OPAMP1_Init(void)
{

  hopamp1.Instance = OPAMP1;
  hopamp1.Init.PowerSupplyRange = OPAMP_POWERSUPPLY_HIGH;
  hopamp1.Init.Mode = OPAMP_PGA_MODE;
  hopamp1.Init.NonInvertingInput = OPAMP_NONINVERTINGINPUT_IO0;
  hopamp1.Init.InvertingInput = OPAMP_INVERTINGINPUT_IO0;
  hopamp1.Init.PgaGain = OPAMP_PGA_GAIN_8;
  hopamp1.Init.PowerMode = OPAMP_POWERMODE_NORMALPOWER;
  hopamp1.Init.UserTrimming = OPAMP_TRIMMING_FACTORY;
  if (HAL_OPAMP_Init(&hopamp1) != HAL_OK)
  {
    Error_Handler();
  }

}

static void MX_RTC_Init(void)
{

  RTC_TimeTypeDef sTime = {0};
  RTC_DateTypeDef sDate = {0};

  /** Initialize RTC Only
  */
  hrtc.Instance = RTC;
  hrtc.Init.HourFormat = RTC_HOURFORMAT_24;
  hrtc.Init.AsynchPrediv = 127;
  hrtc.Init.SynchPrediv = 255;
  hrtc.Init.OutPut = RTC_OUTPUT_DISABLE;
  hrtc.Init.OutPutRemap = RTC_OUTPUT_REMAP_NONE;
  hrtc.Init.OutPutPolarity = RTC_OUTPUT_POLARITY_HIGH;
  hrtc.Init.OutPutType = RTC_OUTPUT_TYPE_OPENDRAIN;
  if (HAL_RTC_Init(&hrtc) != HAL_OK)
  {
    Error_Handler();
  }

  /** Initialize RTC and set the Time and Date
  */
  sTime.Hours = 0x0;
  sTime.Minutes = 0x0;
  sTime.Seconds = 0x0;
  sTime.DayLightSaving = RTC_DAYLIGHTSAVING_NONE;
  sTime.StoreOperation = RTC_STOREOPERATION_RESET;
  if (HAL_RTC_SetTime(&hrtc, &sTime, RTC_FORMAT_BCD) != HAL_OK)
  {
    Error_Handler();
  }
  sDate.WeekDay = RTC_WEEKDAY_MONDAY;
  sDate.Month = RTC_MONTH_JANUARY;
  sDate.Date = 0x1;
  sDate.Year = 0x0;

  if (HAL_RTC_SetDate(&hrtc, &sDate, RTC_FORMAT_BCD) != HAL_OK)
  {
    Error_Handler();
  }

}

static void MX_SPI1_Init(void)
{

  /* SPI1 parameter configuration*/
  hspi1.Instance = SPI1;
  hspi1.Init.Mode = SPI_MODE_MASTER;
  hspi1.Init.Direction = SPI_DIRECTION_2LINES;
  hspi1.Init.DataSize = SPI_DATASIZE_8BIT;
  hspi1.Init.CLKPolarity = SPI_POLARITY_HIGH;
  hspi1.Init.CLKPhase = SPI_PHASE_1EDGE;
  hspi1.Init.NSS = SPI_NSS_SOFT;
  hspi1.Init.BaudRatePrescaler = SPI_BAUDRATEPRESCALER_16;
  hspi1.Init.FirstBit = SPI_FIRSTBIT_MSB;
  hspi1.Init.TIMode = SPI_TIMODE_DISABLE;
  hspi1.Init.CRCCalculation = SPI_CRCCALCULATION_DISABLE;
  hspi1.Init.CRCPolynomial = 7;
  hspi1.Init.CRCLength = SPI_CRC_LENGTH_DATASIZE;
  hspi1.Init.NSSPMode = SPI_NSS_PULSE_DISABLE;
  if (HAL_SPI_Init(&hspi1) != HAL_OK)
  {
    Error_Handler();
  }

}

static void MX_TIM1_Init(void)
{

  /* USER CODE BEGIN TIM1_Init 0 */
  errorcode = 991; // Error_Handler morse_trap code
  /* USER CODE END TIM1_Init 0 */

  TIM_ClockConfigTypeDef sClockSourceConfig = {0};
  TIM_MasterConfigTypeDef sMasterConfig = {0};
  TIMEx_BreakInputConfigTypeDef sBreakInputConfig = {0};
  TIM_OC_InitTypeDef sConfigOC = {0};
  TIM_BreakDeadTimeConfigTypeDef sBreakDeadTimeConfig = {0};

  /* USER CODE BEGIN TIM1_Init 1 */
  errorcode = 992; // Error_Handler morse_trap code
     /* *** Note: the following htim1.Init.Period setting is
            overwritten in chgr_items.c initialization
            using the parameter tim1_arr_init from the
            parameter file.
     *** */
  /* USER CODE END TIM1_Init 1 */
  htim1.Instance = TIM1;
  htim1.Init.Prescaler = 0;
  htim1.Init.CounterMode = TIM_COUNTERMODE_UP;
  htim1.Init.Period = 79;
  htim1.Init.ClockDivision = TIM_CLOCKDIVISION_DIV1;
  htim1.Init.RepetitionCounter = 0;
  htim1.Init.AutoReloadPreload = TIM_AUTORELOAD_PRELOAD_DISABLE;
  if (HAL_TIM_Base_Init(&htim1) != HAL_OK)
  {
    Error_Handler();
  }
  sClockSourceConfig.ClockSource = TIM_CLOCKSOURCE_INTERNAL;
  if (HAL_TIM_ConfigClockSource(&htim1, &sClockSourceConfig) != HAL_OK)
  {
    Error_Handler();
  }
  if (HAL_TIM_PWM_Init(&htim1) != HAL_OK)
  {
    Error_Handler();
  }
  sMasterConfig.MasterOutputTrigger = TIM_TRGO_RESET;
  sMasterConfig.MasterOutputTrigger2 = TIM_TRGO2_RESET;
  sMasterConfig.MasterSlaveMode = TIM_MASTERSLAVEMODE_DISABLE;
  if (HAL_TIMEx_MasterConfigSynchronization(&htim1, &sMasterConfig) != HAL_OK)
  {
    Error_Handler();
  }
  sBreakInputConfig.Source = TIM_BREAKINPUTSOURCE_BKIN;
  sBreakInputConfig.Enable = TIM_BREAKINPUTSOURCE_ENABLE;
  sBreakInputConfig.Polarity = TIM_BREAKINPUTSOURCE_POLARITY_HIGH;
  if (HAL_TIMEx_ConfigBreakInput(&htim1, TIM_BREAKINPUT_BRK, &sBreakInputConfig) != HAL_OK)
  {
    Error_Handler();
  }
  sBreakInputConfig.Source = TIM_BREAKINPUTSOURCE_COMP2;
  if (HAL_TIMEx_ConfigBreakInput(&htim1, TIM_BREAKINPUT_BRK, &sBreakInputConfig) != HAL_OK)
  {
    Error_Handler();
  }
  sBreakInputConfig.Source = TIM_BREAKINPUTSOURCE_BKIN;
  if (HAL_TIMEx_ConfigBreakInput(&htim1, TIM_BREAKINPUT_BRK2, &sBreakInputConfig) != HAL_OK)
  {
    Error_Handler();
  }
  sBreakInputConfig.Source = TIM_BREAKINPUTSOURCE_COMP1;
  if (HAL_TIMEx_ConfigBreakInput(&htim1, TIM_BREAKINPUT_BRK2, &sBreakInputConfig) != HAL_OK)
  {
    Error_Handler();
  }
  sConfigOC.OCMode = TIM_OCMODE_PWM1;
  sConfigOC.Pulse = 0;
  sConfigOC.OCPolarity = TIM_OCPOLARITY_HIGH;
  sConfigOC.OCNPolarity = TIM_OCNPOLARITY_HIGH;
  sConfigOC.OCFastMode = TIM_OCFAST_DISABLE;
  sConfigOC.OCIdleState = TIM_OCIDLESTATE_RESET;
  sConfigOC.OCNIdleState = TIM_OCNIDLESTATE_RESET;
  if (HAL_TIM_PWM_ConfigChannel(&htim1, &sConfigOC, TIM_CHANNEL_1) != HAL_OK)
  {
    Error_Handler();
  }
  sBreakDeadTimeConfig.OffStateRunMode = TIM_OSSR_ENABLE;
  sBreakDeadTimeConfig.OffStateIDLEMode = TIM_OSSI_ENABLE;
  sBreakDeadTimeConfig.LockLevel = TIM_LOCKLEVEL_OFF;
  sBreakDeadTimeConfig.DeadTime = 0;
  sBreakDeadTimeConfig.BreakState = TIM_BREAK_ENABLE;
  sBreakDeadTimeConfig.BreakPolarity = TIM_BREAKPOLARITY_HIGH;
  sBreakDeadTimeConfig.BreakFilter = 0;
  sBreakDeadTimeConfig.Break2State = TIM_BREAK2_ENABLE;
  sBreakDeadTimeConfig.Break2Polarity = TIM_BREAK2POLARITY_HIGH;
  sBreakDeadTimeConfig.Break2Filter = 0;
  sBreakDeadTimeConfig.AutomaticOutput = TIM_AUTOMATICOUTPUT_ENABLE;
  if (HAL_TIMEx_ConfigBreakDeadTime(&htim1, &sBreakDeadTimeConfig) != HAL_OK)
  {
    Error_Handler();
  }
  HAL_TIM_MspPostInit(&htim1);

}

static void MX_TIM2_Init(void)
{

  /* USER CODE BEGIN TIM2_Init 0 */
  errorcode = 993; // Error_Handler morse_trap code
  /* USER CODE END TIM2_Init 0 */

  TIM_ClockConfigTypeDef sClockSourceConfig = {0};
  TIM_MasterConfigTypeDef sMasterConfig = {0};
  TIM_OC_InitTypeDef sConfigOC = {0};

  htim2.Instance = TIM2;
  htim2.Init.Prescaler = 0;
  htim2.Init.CounterMode = TIM_COUNTERMODE_UP;
  htim2.Init.Period = 4294967295;
  htim2.Init.ClockDivision = TIM_CLOCKDIVISION_DIV1;
  htim2.Init.AutoReloadPreload = TIM_AUTORELOAD_PRELOAD_DISABLE;
  if (HAL_TIM_Base_Init(&htim2) != HAL_OK)
  {
    Error_Handler();
  }
  sClockSourceConfig.ClockSource = TIM_CLOCKSOURCE_INTERNAL;
  if (HAL_TIM_ConfigClockSource(&htim2, &sClockSourceConfig) != HAL_OK)
  {
    Error_Handler();
  }
  if (HAL_TIM_PWM_Init(&htim2) != HAL_OK)
  {
    Error_Handler();
  }
  sMasterConfig.MasterOutputTrigger = TIM_TRGO_RESET;
  sMasterConfig.MasterSlaveMode = TIM_MASTERSLAVEMODE_DISABLE;
  if (HAL_TIMEx_MasterConfigSynchronization(&htim2, &sMasterConfig) != HAL_OK)
  {
    Error_Handler();
  }
  sConfigOC.OCMode = TIM_OCMODE_PWM1;
  sConfigOC.Pulse = 0;
  sConfigOC.OCPolarity = TIM_OCPOLARITY_HIGH;
  sConfigOC.OCFastMode = TIM_OCFAST_DISABLE;
  if (HAL_TIM_PWM_ConfigChannel(&htim2, &sConfigOC, TIM_CHANNEL_1) != HAL_OK)
  {
    Error_Handler();
  }
  /* USER CODE BEGIN TIM2_Init 2 */
  errorcode = 994; // Error_Handler morse_trap code

  /* USER CODE END TIM2_Init 2 */
  HAL_TIM_MspPostInit(&htim2);

}

static void MX_TIM15_Init(void)
{

  /* USER CODE BEGIN TIM15_Init 0 */
  errorcode = 995; // Error_Handler morse_trap code

  /* USER CODE END TIM15_Init 0 */

  TIM_ClockConfigTypeDef sClockSourceConfig = {0};
  TIM_MasterConfigTypeDef sMasterConfig = {0};
  TIM_OC_InitTypeDef sConfigOC = {0};
  TIM_BreakDeadTimeConfigTypeDef sBreakDeadTimeConfig = {0};

  htim15.Instance = TIM15;
  htim15.Init.Prescaler = 16;
  htim15.Init.CounterMode = TIM_COUNTERMODE_UP;
  htim15.Init.Period = 65535;
  htim15.Init.ClockDivision = TIM_CLOCKDIVISION_DIV1;
  htim15.Init.RepetitionCounter = 0;
  htim15.Init.AutoReloadPreload = TIM_AUTORELOAD_PRELOAD_DISABLE;
  if (HAL_TIM_Base_Init(&htim15) != HAL_OK)
  {
    Error_Handler();
  }
  sClockSourceConfig.ClockSource = TIM_CLOCKSOURCE_INTERNAL;
  if (HAL_TIM_ConfigClockSource(&htim15, &sClockSourceConfig) != HAL_OK)
  {
    Error_Handler();
  }
  if (HAL_TIM_OC_Init(&htim15) != HAL_OK)
  {
    Error_Handler();
  }
  sMasterConfig.MasterOutputTrigger = TIM_TRGO_RESET;
  sMasterConfig.MasterSlaveMode = TIM_MASTERSLAVEMODE_DISABLE;
  if (HAL_TIMEx_MasterConfigSynchronization(&htim15, &sMasterConfig) != HAL_OK)
  {
    Error_Handler();
  }
  sConfigOC.OCMode = TIM_OCMODE_TIMING;
  sConfigOC.Pulse = 0;
  sConfigOC.OCPolarity = TIM_OCPOLARITY_HIGH;
  sConfigOC.OCNPolarity = TIM_OCNPOLARITY_HIGH;
  sConfigOC.OCFastMode = TIM_OCFAST_DISABLE;
  sConfigOC.OCIdleState = TIM_OCIDLESTATE_RESET;
  sConfigOC.OCNIdleState = TIM_OCNIDLESTATE_RESET;
  if (HAL_TIM_OC_ConfigChannel(&htim15, &sConfigOC, TIM_CHANNEL_1) != HAL_OK)
  {
    Error_Handler();
  }
  sBreakDeadTimeConfig.OffStateRunMode = TIM_OSSR_DISABLE;
  sBreakDeadTimeConfig.OffStateIDLEMode = TIM_OSSI_DISABLE;
  sBreakDeadTimeConfig.LockLevel = TIM_LOCKLEVEL_OFF;
  sBreakDeadTimeConfig.DeadTime = 0;
  sBreakDeadTimeConfig.BreakState = TIM_BREAK_DISABLE;
  sBreakDeadTimeConfig.BreakPolarity = TIM_BREAKPOLARITY_HIGH;
  sBreakDeadTimeConfig.AutomaticOutput = TIM_AUTOMATICOUTPUT_DISABLE;
  if (HAL_TIMEx_ConfigBreakDeadTime(&htim15, &sBreakDeadTimeConfig) != HAL_OK)
  {
    Error_Handler();
  }

}

static void MX_USART1_UART_Init(void)
{

  /* USER CODE BEGIN USART1_Init 0 */
  errorcode = 996; // Error_Handler morse_trap code

  /* USER CODE END USART1_Init 0 */

  huart1.Instance = USART1;
  huart1.Init.BaudRate = 115200;
  huart1.Init.WordLength = UART_WORDLENGTH_8B;
  huart1.Init.StopBits = UART_STOPBITS_1;
  huart1.Init.Parity = UART_PARITY_NONE;
  huart1.Init.Mode = UART_MODE_TX_RX;
  huart1.Init.HwFlowCtl = UART_HWCONTROL_NONE;
  huart1.Init.OverSampling = UART_OVERSAMPLING_8;
  huart1.Init.OneBitSampling = UART_ONE_BIT_SAMPLE_DISABLE;
  huart1.AdvancedInit.AdvFeatureInit = UART_ADVFEATURE_NO_INIT;
  if (HAL_UART_Init(&huart1) != HAL_OK)
  {
    Error_Handler();
  }

}

static void MX_DMA_Init(void)
{

  /* DMA controller clock enable */
  __HAL_RCC_DMA2_CLK_ENABLE();
  __HAL_RCC_DMA1_CLK_ENABLE();

  /* DMA interrupt init */
  /* DMA1_Channel1_IRQn interrupt configuration */
  HAL_NVIC_SetPriority(DMA1_Channel1_IRQn, 6, 0);
  HAL_NVIC_EnableIRQ(DMA1_Channel1_IRQn);
  /* DMA1_Channel2_IRQn interrupt configuration */
  HAL_NVIC_SetPriority(DMA1_Channel2_IRQn, 5, 0);
  HAL_NVIC_EnableIRQ(DMA1_Channel2_IRQn);
  /* DMA1_Channel3_IRQn interrupt configuration */
  HAL_NVIC_SetPriority(DMA1_Channel3_IRQn, 5, 0);
  HAL_NVIC_EnableIRQ(DMA1_Channel3_IRQn);
  /* DMA1_Channel4_IRQn interrupt configuration */
  HAL_NVIC_SetPriority(DMA1_Channel4_IRQn, 5, 0);
  HAL_NVIC_EnableIRQ(DMA1_Channel4_IRQn);
  /* DMA1_Channel5_IRQn interrupt configuration */
  HAL_NVIC_SetPriority(DMA1_Channel5_IRQn, 5, 0);
  HAL_NVIC_EnableIRQ(DMA1_Channel5_IRQn);
  /* DMA2_Channel6_IRQn interrupt configuration */
  HAL_NVIC_SetPriority(DMA2_Channel6_IRQn, 6, 0);
  HAL_NVIC_EnableIRQ(DMA2_Channel6_IRQn);
  /* DMA2_Channel7_IRQn interrupt configuration */
  HAL_NVIC_SetPriority(DMA2_Channel7_IRQn, 6, 0);
  HAL_NVIC_EnableIRQ(DMA2_Channel7_IRQn);

}

static void MX_GPIO_Init(void)
{
  GPIO_InitTypeDef GPIO_InitStruct = {0};

  /* GPIO Ports Clock Enable */
  __HAL_RCC_GPIOC_CLK_ENABLE();
  __HAL_RCC_GPIOH_CLK_ENABLE();
  __HAL_RCC_GPIOA_CLK_ENABLE();
  __HAL_RCC_GPIOB_CLK_ENABLE();
  __HAL_RCC_GPIOD_CLK_ENABLE();

  /*Configure GPIO pin Output Level */
  HAL_GPIO_WritePin(GPIOC, RTC_BAT_PWR_Pin|DUMP2_Pin|DUMP_NOT_Pin|DUMP_Pin
                          |HEATER_NOT_Pin|HEATER_Pin, GPIO_PIN_RESET);

  /*Configure GPIO pin Output Level */
  HAL_GPIO_WritePin(GPIOB, LED_GRN_Pin|LED_RED_Pin, GPIO_PIN_SET);

  /*Configure GPIO pin Output Level */
  HAL_GPIO_WritePin(GPIOB, PADxx_Pin|PAD7_Pin, GPIO_PIN_RESET);

  /*Configure GPIO pin Output Level */
  HAL_GPIO_WritePin(CSB_GPIO_Port, CSB_Pin, GPIO_PIN_RESET);

  /*Configure GPIO pin Output Level */
  HAL_GPIO_WritePin(BQ_LD_GPIO_Port, BQ_LD_Pin, GPIO_PIN_RESET);

  /*Configure GPIO pins : RTC_BAT_PWR_Pin DUMP_NOT_Pin DUMP_Pin HEATER_NOT_Pin
                           HEATER_Pin */
  GPIO_InitStruct.Pin = RTC_BAT_PWR_Pin|DUMP_NOT_Pin|DUMP_Pin|HEATER_NOT_Pin
                          |HEATER_Pin;
  GPIO_InitStruct.Mode = GPIO_MODE_OUTPUT_PP;
  GPIO_InitStruct.Pull = GPIO_NOPULL;
  GPIO_InitStruct.Speed = GPIO_SPEED_FREQ_LOW;
  HAL_GPIO_Init(GPIOC, &GPIO_InitStruct);

  /*Configure GPIO pins : LED_GRN_Pin LED_RED_Pin PADxx_Pin PAD7_Pin */
  GPIO_InitStruct.Pin = LED_GRN_Pin|LED_RED_Pin|PADxx_Pin|PAD7_Pin;
  GPIO_InitStruct.Mode = GPIO_MODE_OUTPUT_PP;
  GPIO_InitStruct.Pull = GPIO_NOPULL;
  GPIO_InitStruct.Speed = GPIO_SPEED_FREQ_LOW;
  HAL_GPIO_Init(GPIOB, &GPIO_InitStruct);

  /*Configure GPIO pin : FANTach_Pin */
  GPIO_InitStruct.Pin = FANTach_Pin;
  GPIO_InitStruct.Mode = GPIO_MODE_IT_RISING;
  GPIO_InitStruct.Pull = GPIO_NOPULL;
  HAL_GPIO_Init(FANTach_GPIO_Port, &GPIO_InitStruct);

  /*Configure GPIO pin : DUMP2_Pin */
  GPIO_InitStruct.Pin = DUMP2_Pin;
  GPIO_InitStruct.Mode = GPIO_MODE_OUTPUT_PP;
  GPIO_InitStruct.Pull = GPIO_PULLDOWN;
  GPIO_InitStruct.Speed = GPIO_SPEED_FREQ_LOW;
  HAL_GPIO_Init(DUMP2_GPIO_Port, &GPIO_InitStruct);

  /*Configure GPIO pin : CSB_Pin */
  GPIO_InitStruct.Pin = CSB_Pin;
  GPIO_InitStruct.Mode = GPIO_MODE_OUTPUT_PP;
  GPIO_InitStruct.Pull = GPIO_NOPULL;
  GPIO_InitStruct.Speed = GPIO_SPEED_FREQ_HIGH;
  HAL_GPIO_Init(CSB_GPIO_Port, &GPIO_InitStruct);

  /*Configure GPIO pin : BQ_LD_Pin */
  GPIO_InitStruct.Pin = BQ_LD_Pin;
  GPIO_InitStruct.Mode = GPIO_MODE_OUTPUT_PP;
  GPIO_InitStruct.Pull = GPIO_NOPULL;
  GPIO_InitStruct.Speed = GPIO_SPEED_FREQ_LOW;
  HAL_GPIO_Init(BQ_LD_GPIO_Port, &GPIO_InitStruct);

  /*Configure GPIO pin : WDT_Pin */
  GPIO_InitStruct.Pin = WDT_Pin;
  GPIO_InitStruct.Mode = GPIO_MODE_IT_RISING;
  GPIO_InitStruct.Pull = GPIO_PULLUP;
  HAL_GPIO_Init(WDT_GPIO_Port, &GPIO_InitStruct);

  /* EXTI interrupt init*/
  HAL_NVIC_SetPriority(EXTI9_5_IRQn, 5, 0);
  HAL_NVIC_EnableIRQ(EXTI9_5_IRQn);

}

/* USER CODE BEGIN Header_StartDefaultTask */
/**
  * @brief  Function implementing the defaultTask thread.
  * @param  argument: Not used
  * @retval None
  */
uint32_t adc1_ctr_prev;
uint32_t fctr = 0;
uint8_t adcctr = 0;
uint8_t wakectr;
uint8_t state_defaultTask = 0;
static struct BMSREQ_Q bmsreq_1;
struct BMSREQ_Q* pbmsreq_1 = &bmsreq_1;
#define LSPC 7 // column spacing
char* pcheader =
"\n\r                 1      2      3      4      5      6      7      8      9     10     11     12     13     14     15     16     17     18";
char* ptripcode ="0123456789ABCDEFGH";
static uint8_t idxtripcode;
static char tripline[LSPC*18+2];
static uint32_t celltrip_prev;
static uint32_t celltrip_time[18];
static uint32_t celltrip_time_offset;
static uint32_t celltrip_time_offset_discharge;
static uint32_t celltrip_time_lo;
static uint8_t hyster_sw_prev;
uint32_t rtcregs_status;
uint32_t rtcregs_morse_code;
uint8_t rtcregs_OK;
/* USER CODE END Header_StartDefaultTask */
void StartDefaultTask(void *argument)
{
  /* USER CODE BEGIN 5 */
  int32_t i;
  uint32_t mctr = 0;

// Poll 'done' so task handle not needed
  //bmsreq_read.bmsTaskHandle   = xTaskGetCurrentTaskHandle();
  //bmsreq_update.bmsTaskHandle = bmsreq_read.msTaskHandle;

  struct SERIALSENDTASKBCB* pbuf1 = getserialbuf(&HUARTMON,144);
  if (pbuf1 == NULL) morse_trap(115);
  struct SERIALSENDTASKBCB* pbuf2 = getserialbuf(&HUARTMON,128);
  if (pbuf2 == NULL) morse_trap(125);
struct SERIALSENDTASKBCB* pbuf3 = getserialbuf(&HUARTMON,128);
if (pbuf3 == NULL) morse_trap(125);
//struct SERIALSENDTASKBCB* pbuf4 = getserialbuf(&HUARTMON,128);
//if (pbuf4 == NULL) morse_trap(125);

  yprintf(&pbuf1,"\n\n\rPROGRAM STARTS: rtcregs_ret: ");
  if (rtcregs_ret == 0)
  {
    yprintf(&pbuf3,"OK");
  }
  else
  {
    yprintf(&pbuf3,"NG");

  }

  /* List the RTC */
  /*
  uint32_t cellbal;       //   1.00 Bits with FETs that were on
  uint32_t hysterbits_lo; //   1.00 Bits for cells that fell below hysterv_lo
  uint16_t cellreg[18];   //   9.00 Last readings before power down
  uint8_t hyster_sw;      //   .125 Hysteresis switch: 1 = peak was reached
  uint8_t battery_status; //   .125 Cell status code bits
  uint8_t fet_status;     //   .125 This controls on/off of FETs
  uint8_t err;            //   .125 Err bits
  uint32_t morse_err;     //   1.00 morse_trap err code
  uint32_t celltrip;      //   1.00 Cell trip bits
  uint16_t morse_err_ct;  //    .50 Count of same morse_trap code
  uint16_t warning;       //    .50 Warning, but not morse_trap'd
 The foregoing MUST be an even number of 32b
  uint16_t pec15; // CRC15 (in lower 1/2 of register)
*/
  if (rtcregs_ret == 0)
  {
    yprintf(&pbuf1,"\n\r\t\tRTC REGISTERS SAVED & RESTORED");
    uint32_t* prtc = (uint32_t*)&RTC->BKP0R;
    yprintf(&pbuf2,"\n\rcellbal: %05X",*prtc++);
    yprintf(&pbuf1,"\n\rhysterbits_lo: %05X",*prtc++);
    yprintf(&pbuf2,"%s",pcheader);
    yprintf(&pbuf1,"\n\r           ");
    for (i = 0; i < 9; i++)
    {
      yprintf(&pbuf1," %6d",(*prtc & 0xFFFF));
      yprintf(&pbuf2," %6d",(*prtc >> 16));
      prtc += 1;
    }
    rtcregs_status = *prtc; // Save for CAN msgs

    yprintf(&pbuf1,"\n\rhyster_sw     : %02X",((*prtc >>  0) & 0xff));
    yprintf(&pbuf2,"\n\rbattery_status: %02X",((*prtc >>  8) & 0xff));
    yprintf(&pbuf1,"\n\rfet_status    : %02X",((*prtc >> 16) & 0xff));
    yprintf(&pbuf2,"\n\rerr           : %02X",((*prtc >> 24) & 0xff));
    prtc += 1;
    rtcregs_morse_code = *prtc; // Save for CAN msgs
    yprintf(&pbuf1,"\n\rmorse_err: %d",*prtc);
     prtc += 1;
    yprintf(&pbuf1,"\n\rcelltrip: 0x%05x\n\n\r",*prtc);
     prtc += 1;
    yprintf(&pbuf2,"\n\rmorse_err_ct  : %d"  ,((*prtc >>  0) & 0xffff));
    yprintf(&pbuf3,"\n\rwarning       : %04X",((*prtc >> 16) & 0xffff));

    osDelay(50); // Allow enough time to printout before next morse_trap
  }

  /* The 'for' loop polls. The following times the loop. */
  #define MAINFORLOOPDELAY 50 // Delay of 'for' loop in ms
  const TickType_t xPeriod = pdMS_TO_TICKS(MAINFORLOOPDELAY);
  TickType_t tickcnt = xTaskGetTickCount();

  bq_items_init(); // Updates tickcnt

//extern uint32_t bmsdbctr;
//uint32_t bmsdbctr_prev = bmsdbctr;
extern uint8_t dbgka;
uint8_t dbgka_prev = dbgka;
extern uint32_t bshift;
extern uint32_t dbstat2;

/* Testint discharge FET bits. */
#ifdef TEST_WALK_DISCHARGE_FET_BITS // See main.h
extern uint8_t dischgfet; // Test fet bit (0-17)
  uint8_t  dischgfet_ctr = 20;
extern  dbgcancommloop;
uint32_t dbgcancommloop_prev;
#endif

uint32_t ticks_secs = 0;
uint32_t ticks_next = xTaskGetTickCount();

//uint32_t dbgsendcellctr_prev=0;
//uint32_t dbgsendcelldtw_prev=0;

  memset(tripline,' ',(LSPC*18));
  for (i = 0; i < 18; i++) tripline[i*LSPC] = '.';
  tripline[18*LSPC] = 0;
  celltrip_prev = 0;

// Test battery switch fet PC13)
//HAL_GPIO_WritePin(GPIOC,GPIO_PIN_13,GPIO_PIN_SET);

  for(;;) /* Loop polls various operations. */
  {
    vTaskDelayUntil( &tickcnt, xPeriod );

    /* Keep a running count of secs. */
    if ( (int)(xTaskGetTickCount() - ticks_next) > 1000)
    {
      ticks_next += 1000;
      ticks_secs += 1;
    }

#if 1 // Processor ADC display
    adcctr += 1;
    if (adcctr > 40)
    {
      adcctr = 0;
  extern uint32_t dwtdiff;
  #if 1
      yprintf(&pbuf1,"\n\rADCf: %4d %6d:",(adc1.ctr-adc1_ctr_prev),dwtdiff);
      adc1_ctr_prev = adc1.ctr;
      for (i = 0; i < 9; i++)
      {
        yprintf(&pbuf2," %6.4f",adc1.abs[i].filt);
      }
      float tcf = adcparams_caltemp();
      yprintf(&pbuf1," temp: %4.1f",tcf);
  #endif

  #if 0
      float tcf1 = adcparams_caltemp();
      yprintf(&pbuf1,"\n\r temp: %6.4f vref %0.5f cal1 %0.1f cal2 %0.1f caldiff %0.4f calrate %0.5f",tcf1,
        adc1.common.ts_vref,
        adc1.common.ts_cal1,      /* (float)(*PTS_CAL1); // Factory calibration */
        adc1.common.ts_cal2,      /* (float)(*PTS_CAL2); // Factory calibration */
        adc1.common.ts_caldiff,   /* (padccommon->ts_cal2 - padccommon->ts_cal1); */
        adc1.common.ts_calrate );
#endif

  #if 1
      yprintf(&pbuf1,"\n\rADCi: %4d %6d",(adc1.ctr-adc1_ctr_prev),dwtdiff);
    extern uint32_t dbg_adcsum[ADCDIRECTMAX];
      yprintf(&pbuf1," %6d %6d %6d %6d %6d %6d %6d %6d %6d",
          dbg_adcsum[0],dbg_adcsum[1],dbg_adcsum[2],dbg_adcsum[3],dbg_adcsum[4],
          dbg_adcsum[5],dbg_adcsum[6],dbg_adcsum[7],dbg_adcsum[8]);
  #endif
      adc1_ctr_prev = adc1.ctr;
    }
#endif

#if 1
    HAL_GPIO_WritePin(GPIOB,GPIO_PIN_0,GPIO_PIN_SET); // GRN LED
    if (dbgka_prev != dbgka)
    {
      dbgka_prev = dbgka;
      HAL_GPIO_WritePin(GPIOB,GPIO_PIN_0,GPIO_PIN_RESET); // GRN LED

      switch (dbgka)
      {
      case 0: // config regs
       yprintf(&pbuf1,"\n\n\r\t\t%5d",mctr++);

       yprintf(&pbuf2,"\n\r%5d CFGR   %04X %04X %04X : %04X %04X %04X %d",dbgka,
          bmsspiall.configreg[0],bmsspiall.configreg[1],bmsspiall.configreg[2],
          bmsspiall.configreg[3],bmsspiall.configreg[4],bmsspiall.configreg[5],bshift+1);
        break;

      case 1: // Stat regs
       yprintf(&pbuf2,"\n\r%5d STAT   %04X %04X %04X : %04X %04X %04X %d ",dbgka,
          bmsspiall.statreg[0],bmsspiall.statreg[1],bmsspiall.statreg[2],
          bmsspiall.statreg[3],bmsspiall.statreg[4],bmsspiall.statreg[5],dbstat2/16);
        break;

      case 2:
       yprintf(&pbuf2,"\n\r%5d SREG   %04X %04X %04X",dbgka,
          bmsspiall.sreg[0],bmsspiall.sreg[1],bmsspiall.sreg[2]);
        break;

      case 3:
       yprintf(&pbuf2,"\n\r%5d WFGR   %04X %04X %04X : %04X %04X %04X",dbgka,
          bmsspiall.configreg[0],bmsspiall.configreg[1],bmsspiall.configreg[2],
          bmsspiall.configreg[3],bmsspiall.configreg[4],bmsspiall.configreg[5]);
        break;

      case 4:
       yprintf(&pbuf1,"%s",pcheader);
       yprintf(&pbuf2,"\n\r%5dADCVAX",dbgka);
       for (i = 0; i < 18; i++) yprintf(&pbuf1," %6d",bmsspiall.cellreg[i]);
       yprintf(&pbuf1," %d",dbstat2/16);
        break;

      case 5: // Temperature (AUX reg)
       yprintf(&pbuf2,"\n\rAUX %6d %6d %6d",bmsspiall.auxreg[0],bmsspiall.auxreg[ 1],bmsspiall.auxreg[ 2]);
       yprintf(&pbuf1," %6d %6d %6d",   bmsspiall.auxreg[3],bmsspiall.auxreg[ 4],bmsspiall.auxreg[ 5]);
       yprintf(&pbuf3," %6d %6d %6d",   bmsspiall.auxreg[6],bmsspiall.auxreg[ 7],bmsspiall.auxreg[ 8]);
       yprintf(&pbuf2," %6d %6d %6d %d",bmsspiall.auxreg[9],bmsspiall.auxreg[10],bmsspiall.auxreg[11], dbstat2/16);

       extern uint32_t dbgaux;
       yprintf(&pbuf1," %d",dbgaux);

      bms_items_extract_statreg();
      yprintf(&pbuf3,"\n\r%5d SC-sumcells:%6.2fv ITMP-internal-temp:%5.1fC VA-analog:%6.3fv VD-digital:%6.3fv",dbgka,
          extractstatreg.sc, extractstatreg.itmp,
          extractstatreg.va, extractstatreg.vd  );

      bms_items_therm_temps(); // Convert thermistor readings to temperature (deg C)
      extern float fanrpm;
      yprintf(&pbuf2,"\n\rTEMP:%5.1f %5.1f %5.1f fanspeed: %d fanrpm: %0.3f",
          bqfunction.lc.thermcal[0].temp,
          bqfunction.lc.thermcal[1].temp,
          bqfunction.lc.thermcal[2].temp,
          bqfunction.fanspeed, fanrpm);

      float cstmp = bms_items_current_sense(); // Calibrate current sense readings
      float cstmphall = bms_items_current_sense_Hall(); // Calibrate current sense readings
      yprintf(&pbuf1,"\n\rCURRENT LINK: %5.1f CURRENT_HALL: %5.1f", cstmp,cstmphall);
        break;

      default:
        yprintf(&pbuf2,"\n\r%d %5d BOGUS",dbgka, mctr);
        break;
      }
    }
#endif

#if 1
    /* Update FAN control. (4/sec) */
    bms_items_therm_temps(); // Convert thermistor readings to temperature (deg C)
    fanop();
#endif

#if 0
/* Check WAKE */

#endif

/* Testing discharge FET bits. */
#ifdef TEST_WALK_DISCHARGE_FET_BITS // See main.h
  if (dischgfet_ctr++ > 3)
  {
    yprintf(&pbuf1,"\n\r\t\t\t\t\t\t### TEST: WALK DISCHARGE FET #%02u %u\n\r",(dischgfet+1),dbgcancommloop-dbgcancommloop_prev);
    dischgfet_ctr = 0;
    dbgcancommloop_prev = dbgcancommloop;
  }
#else
    /* ========> Cell balance & control. <========*/
    uint32_t dcc = extractconfigreg.dcc;
    char cline[LSPC*18+2];

    /* Check cell balance. */
    uint8_t ret8 = bq_items();
    if (ret8 == 2)
    { // Here a cell balance update was completed
      bms_items_extract_configreg();
extern uint8_t dbgf;
//extern struct BMSREQ_Q  bmstask_q_readbms;
//      yprintf(&pbuf1,"\n\r    %05X   ",bmstask_q_readbms.setfets);
//      for (i=0; i < 18; i++) yprintf(&pbuf2,"%4d",(1+i));
      yprintf(&pbuf1,"%s",pcheader);

int32_t csum = 0;
      yprintf(&pbuf2,"\n\rJcellv[i]: ");
      for (i = 0; i < 18; ++i)
      {
        csum += bqfunction.cellv[i];
        yprintf(&pbuf2," %6.0f",bqfunction.cellv[i]);
      }
      yprintf(&pbuf1," %d",csum);

#if 0 // Display cell registers after CLRCELL command
extern uint16_t clrregs[18];
      yprintf(&pbuf2,"\n\rCLRCELL  : ");
      for (i = 0; i < 18; ++i)
      {
        yprintf(&pbuf1," %6.0d",clrregs[i]);
      }
#endif
      // Line with FETs turned ON
      yprintf(&pbuf2,"\n\r%5d %02d FETS    ",fctr++,dbgf+1);
      memset(cline,' ',(LSPC*18));
      // Build a nice ASCII line whilst previous line prints
      for (i=0; i < 18; i++)
      {
        if ((dcc & (1<<i)) != 0)
          cline[i*LSPC] = '#'; // ON
        else
          cline[i*LSPC] = '.'; // OFF
      }
      cline[18*LSPC] = 0; // Output line
      yprintf(&pbuf1,"%s",cline);

      // Line with cells tripped (over max) and trip sequence (0 to max H)
      yprintf(&pbuf2,"\n\r%5d %02d TRIPPED ",fctr,dbgf+1);
      if(bqfunction.celltrip == 0)
      { // Reset display line
        for (i = 0; i < 18; i++) tripline[i*LSPC] = '.';
        idxtripcode = 0;
        celltrip_prev = 0;
      }

      // tmptime is from last boot or switch from discharge to charge
      uint32_t tmptime = (ticks_secs - celltrip_time_offset);

      // Check for any changes in tripped cells
      uint32_t ttx = bqfunction.celltrip ^ celltrip_prev;
      if (ttx != 0)
      {
        if (idxtripcode >= 18) morse_trap(333);
        for (i=0; i < 18; i++)
        {
          if ((ttx & (1<<i)) != 0)
          { // Cell trip
              tripline[i*LSPC] = *(ptripcode+idxtripcode);
          }
        }
        idxtripcode += 1;
        celltrip_prev = bqfunction.celltrip;
      }
      yprintf(&pbuf1,"%s",tripline);

yprintf(&pbuf2," %08X",bqfunction.lc.cid_msg_bms_cellvsmr);

      // Time cell tripped
      yprintf(&pbuf2,"\n\rTRIPT %5d",tmptime);
        for (i=0; i < 18; i++)
        {
          if ((bqfunction.celltrip & (1<<i)) == 0)
          {
            if ((bqfunction.battery_status & BSTATUS_CHARGING) != 0)
              celltrip_time[i] = tmptime; // Save time of trip
          }
          yprintf(&pbuf1,"%7d",celltrip_time[i]);
        }

     // Reset time reference when change is to charging (from self-discharging)
      if (hyster_sw_prev != bqfunction.hyster_sw)
      { // Changed charge/relaxation status
        hyster_sw_prev = bqfunction.hyster_sw;

        if (bqfunction.hyster_sw == 0)
        { // Change to charging
          // Save start of charging time
          celltrip_time_offset = ticks_secs;
          // Zero out time-to-trip max for each cell.
          for (i=0; i < 18; i++) celltrip_time[i] = 0;
        }
        else
        { // Changed to relaxation (all cells tripped)
          celltrip_time_offset_discharge = ticks_secs;
        }
      }

      yprintf(&pbuf1,"\n\r%5d %02d MAX|MIN ",fctr,dbgf+1);
      memset(cline,' ',(LSPC*18));
      // Build a nice ASCII line whilst previous line prints
      for (i=0; i < 18; i++)
      {
        cline[i*LSPC] = '.';
        if ((bqfunction.cellv_max_bits & (1<<i)) != 0)
          cline[i*LSPC] = '+';
        if ((bqfunction.cellv_min_bits & (1<<i)) != 0)
          cline[i*LSPC] = '-';
      }
      cline[18*LSPC] = 0; // Line terminatior
      yprintf(&pbuf2,"%s",cline);

      yprintf(&pbuf1,"\n\rLOWTRIP          ");
      memset(cline,' ',(LSPC*18));
      // Build a nice ASCII line whilst previous line prints
      for (i=0; i < 18; i++)
      {
        cline[i*LSPC] = '.';
        if ((bqfunction.hysterbits_lo_save & (1<<i)) != 0)
          cline[i*LSPC] = 'o';
        else
          cline[i*LSPC] = '.';
      }
      cline[18*LSPC] = 0; // Line terminatior
      yprintf(&pbuf2,"%s",cline);

      /* During discharge the elapsed time since tripped max displays.
      and during charge it doesn't change. */
      if (bqfunction.hyster_sw != 0)
      {
        celltrip_time_lo = ticks_secs - celltrip_time_offset_discharge;
      }
      yprintf(&pbuf1,"\n\rhyster_sw: %d hysterbits lo 0x%05X, discharge_test_sw: %d discharge time: %5d (secs)",
        bqfunction.hyster_sw,
        bqfunction.hysterbits_lo,
        bqfunction.discharge_test_sw,
        celltrip_time_lo );
      float ftmp = celltrip_time_lo;
      yprintf(&pbuf2," %0.3f (hrs)",ftmp/3600.0);

extern uint32_t dbgtrc;
      yprintf(&pbuf1,"\n\rFETSTAT: 0x%02X  battery_status: 0x%02X dbgtrc: 0x%05x ",
        bqfunction.fet_status,
        bqfunction.battery_status,
        dbgtrc);

      yprintf(&pbuf2,"\n\rbqreq[]: %d %d %d",bqfunction.bqreq[0],bqfunction.bqreq[1],bqfunction.bqreq[2]);

#if 0 // spibms readout duration
extern uint32_t dbgread2;
extern uint32_t dbgexttim2;
  float f1 = dbgread2/16.0;
  float f2 = dbgexttim2/16.0;

      yprintf(&pbuf2,"\t dbgextim2: %d %0.1f dbgread2 ; %d %0.1f",dbgexttim2,f2, dbgread2,f1);
      dbgexttim2 = 0;
      dbgread2 = 0;
#endif

#if 0
      yprintf(&pbuf1,"\n\rcellv_latest[i]: ");
      for (i = 0; i < 18; ++i) yprintf(&pbuf2," %5d",bqfunction.cellv_latest[i]);
#endif
      yprintf(&pbuf2,"\n\rcellspresent: 0x%05X celltrip: 0x%05X",bqfunction.cellspresent,bqfunction.celltrip);
      yprintf(&pbuf1,"\n\rcellv_hi: #%2d %5dmv",bqfunction.cellx_high+1,bqfunction.cellv_high);
      yprintf(&pbuf3,    " cellv_high_f: %7.1f",bqfunction.cellv_high_f*0.1);
      yprintf(&pbuf2,"\n\rcellv_lo: #%2d %5dmv",bqfunction.cellx_low+1, bqfunction.cellv_low);
      yprintf(&pbuf1,    "  cellv_low_f: %7.1f",bqfunction.cellv_low_f*0.1);
      yprintf(&pbuf3,"   diff: %7.1f",(bqfunction.cellv_high_f - bqfunction.cellv_low_f)*0.1);
      yprintf(&pbuf2,"\n\rcellv_tmdelta:%5dmv",bqfunction.cellv_tmdelta);
      yprintf(&pbuf1,"    bqfunction.cellv_sum_f: %7.2fv",bqfunction.cellv_sum_f*0.0001);
      yprintf(&pbuf3,"\n\rhysterv_lo:    %6.1fmv",bqfunction.hysterv_lo);
      yprintf(&pbuf2,"\n\rcellv_max: %5d cellv_max_bits: 0x%05X",bqfunction.lc.cellv_max,bqfunction.cellv_max_bits);
      yprintf(&pbuf1," cellv_min: %5d cellv_min_bits: 0x%05X",bqfunction.lc.cellv_min,bqfunction.cellv_min_bits);
      yprintf(&pbuf3," cellv_vls: %5d cellv_vlc_bits: 0x%05X",bqfunction.lc.cellv_vlc, bqfunction.cellv_vlc_bits);
      yprintf(&pbuf2,"\n\rcellbal: 0x%05X cansetfet: 0x%05X  fet_status: 0x%04X FET_CHRG: 0x%01X",bqfunction.cellbal,
          bqfunction.cansetfet,
          bqfunction.fet_status,(bqfunction.fet_status & FET_CHGR));
      if ((bqfunction.fet_status & FET_DUMP2) != 0)
        yprintf(&pbuf1,"\t\t\t\t\tDUMP2 ON");
      else
        yprintf(&pbuf1,"\t\t\t\t\tDUMP2 OFF");
yprintf(&pbuf1,"\n\rcanset_tim diff: %d cansetfet: 0x%06X",(int)(xTaskGetTickCount() - bqfunction.cansetfet_tim),bqfunction.cansetfet);

/* Check for overrun of canmsg payload. */
for (i = 0; i < 4; i++)
{
  if (bqfunction.pad[i] != 0)
    yprintf(&pbuf1,"\n\rPAD[%d] %d 0X%X",bqfunction.pad[i],bqfunction.pad[i]);
}

//      yprintf(&pbuf2,"\t %08X",bqfunction.lc.cid_msg_bms_cellvsmr); // CAN ID

      extern uint32_t dbgcellbal;
      yprintf(&pbuf1,"\n\rdbgcellbal:%05X",dbgcellbal);

      yprintf(&pbuf2,"\n\r config:   %04X %04X %04X %04X %04X %04X",
        bmsspiall.configreg[0],bmsspiall.configreg[1],bmsspiall.configreg[2],
        bmsspiall.configreg[3],bmsspiall.configreg[4],bmsspiall.configreg[5]);

    if (bmsspiall.err1ct != 0)
    {
      yprintf(&pbuf1,"\n\n\r### LOOPCTR ERR: %d\n\r",bmsspiall.err1ct);
      bmsspiall.err1ct = 0;
    }
extern uint32_t dbgCanTask1;
yprintf(&pbuf3,"\n\rdbCanTask1: %d", dbgCanTask1);

  #if 0 /* RTC register check. */
  switch (state_defaultTask)
  {
    case 0:
      bmsreq_1.reqcode = REQ_RTCREAD;
      bmsreq_1.done = 1; // Show req is queued
      int ret = xQueueSendToBack(BMSTaskReadReqQHandle, &pbmsreq_1, 0);
      if (ret != pdPASS) morse_trap(109);
      state_defaultTask = 1;
    case 1:
      if (bmsreq_1.done != 0)
        break;
      uint32_t* prtc32 = (uint32_t*)&RTC->BKP0R;
      yprintf(&pbuf1,"\n\rRTC: F:%05X H:%05X L:%05X",*(prtc32+0),*(prtc32+1),*(prtc32+2));

      uint16_t* prtc16 = (uint16_t*)&RTC->BKP0R + 6;
      for (i = 0; i < 18; i++)
      {
        yprintf(&pbuf2," %5d",*prtc16);
        prtc16 += 1;
      }

      uint8_t* prtc8 = (uint8_t*)prtc16;
      yprintf(&pbuf1," H:%02X B:%02X F:%02X E:%02X ",*(prtc8+0),*(prtc8+1),*(prtc8+2),*(prtc8+3));

      if (bmsreq_1.other == 0)
      {
        yprintf(&pbuf2," OK");
      }
      else
      {
        yprintf(&pbuf2," NOT OK");
        /* if NOT OK do an update. */
        bmsreq_1.reqcode = REQ_RTCUPDATE;
        bmsreq_1.done = 1; // Show req is queued
        int ret = xQueueSendToBack(BMSTaskReadReqQHandle, &pbmsreq_1, 0);
        if (ret != pdPASS) morse_trap(108);
        state_defaultTask = 2;
      }
    case 2:
      if (bmsreq_1.done != 0)
        break;
      state_defaultTask = 0;
      break;
  }
  #endif
    }
#endif
  }

  /* USER CODE END 5 */
}

void HAL_TIM_PeriodElapsedCallback(TIM_HandleTypeDef *htim)
{
  if (htim->Instance == TIM16) {
    HAL_IncTick();
  }
}

void Error_Handler(void)
{
  /* USER CODE BEGIN Error_Handler_Debug */
  /* User can add his own implementation to report the HAL error return state */
  morse_trap(2222);
  __disable_irq();
  while (1)
  {
  }
  /* USER CODE END Error_Handler_Debug */
}

#ifdef  USE_FULL_ASSERT
/**
  * @brief  Reports the name of the source file and the source line number
  *         where the assert_param error has occurred.
  * @param  file: pointer to the source file name
  * @param  line: assert_param error line source number
  * @retval None
  */
void assert_failed(uint8_t *file, uint32_t line)
{
  /* USER CODE BEGIN 6 */
  /* User can add his own implementation to report the file name and line number,
     ex: printf("Wrong parameters value: file %s on line %d\r\n", file, line) */
  morse_trap(3333);
  /* USER CODE END 6 */
}
#endif /* USE_FULL_ASSERT */

/************************ (C) COPYRIGHT STMicroelectronics *****END OF FILE****/
